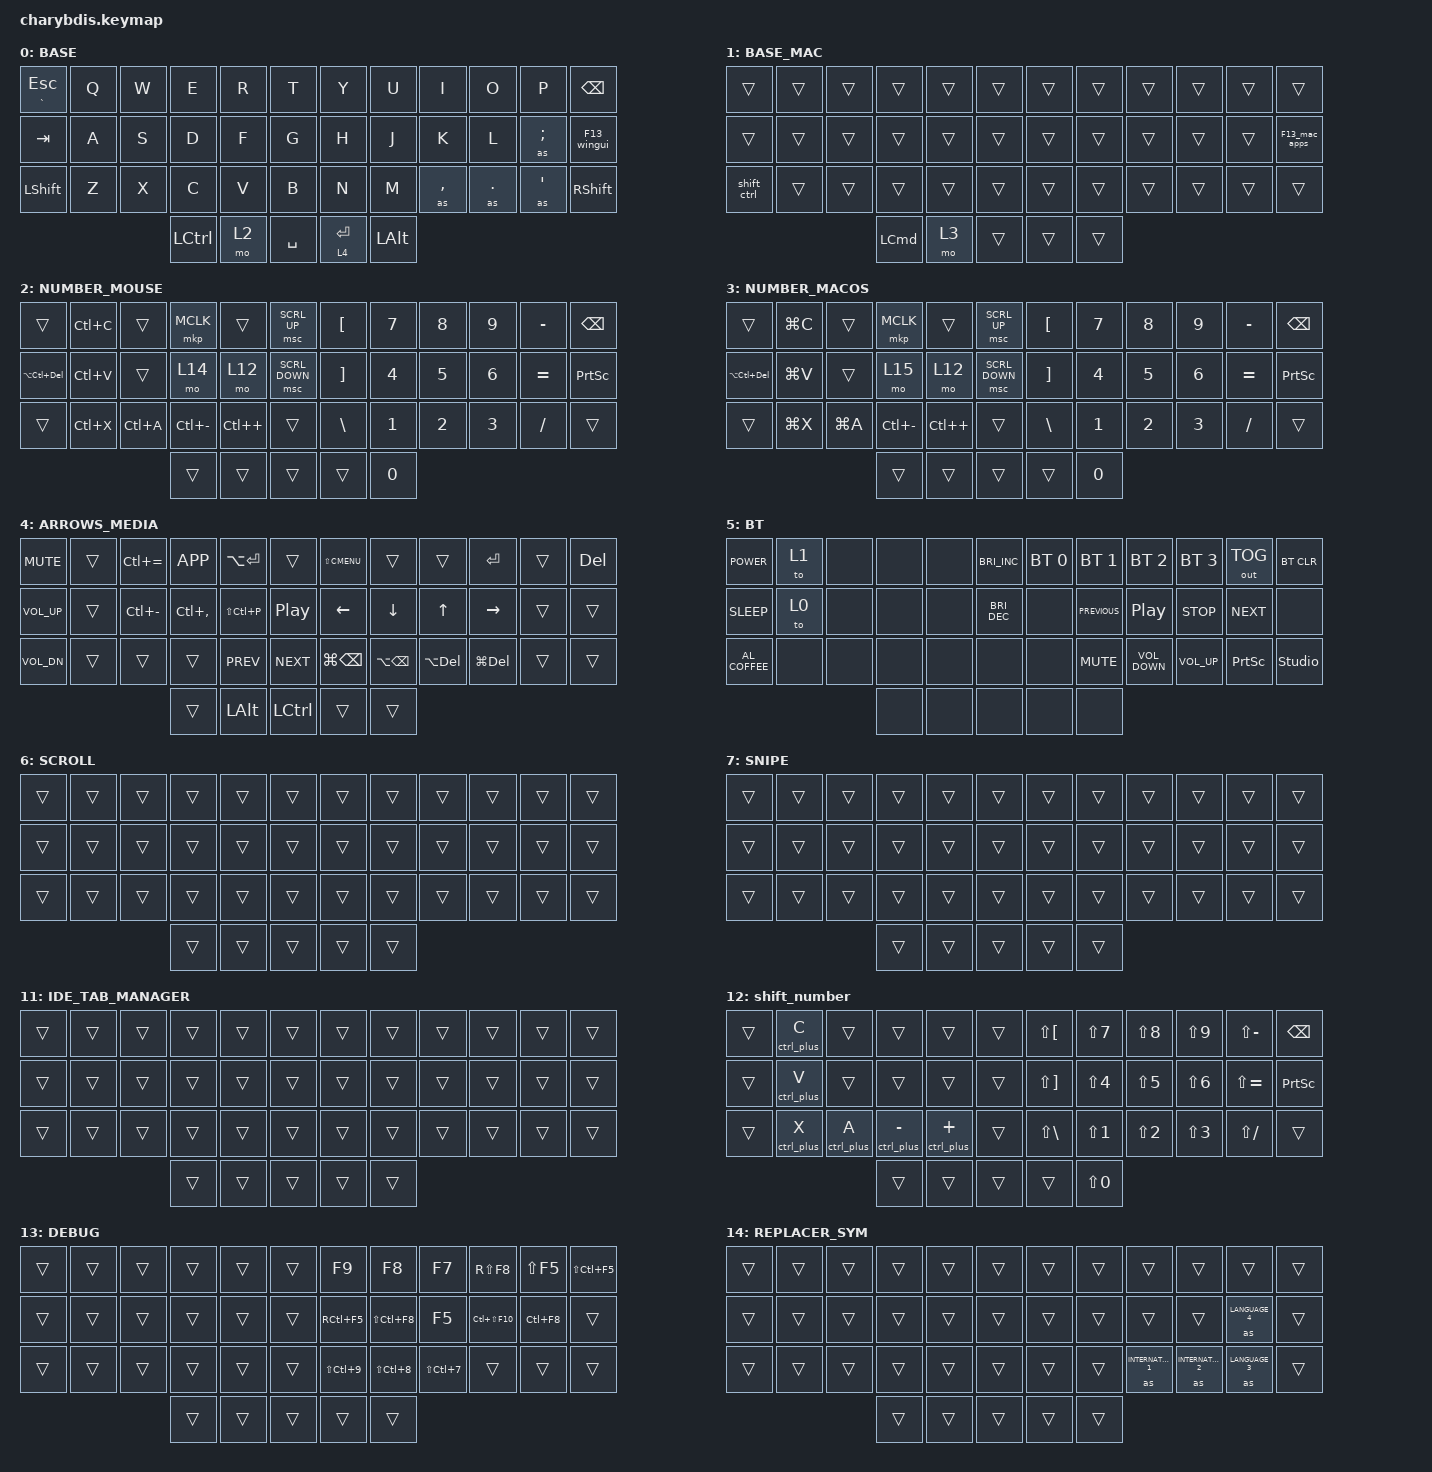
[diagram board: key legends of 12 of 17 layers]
#include <dt-bindings/zmk/mouse.h>
#include <behaviors/mouse_keys.dtsi>

#define MACRO_PLACEHOLDER 0

// #include "macros.dtsi"
// #include "behaviors.dtsi"
// #include "combos.dtsi"
// #include <behaviors.dtsi>

#include <behaviors.dtsi>
#include <dt-bindings/zmk/bt.h>
#include <dt-bindings/zmk/keys.h>
#include <dt-bindings/zmk/outputs.h>
#include <dt-bindings/zmk/pointing.h>

/ {
    /* input config for mouse move mode */

    trackball_listener {
        compatible = "zmk,input-behavior-listener";
        device = <&vtrackball>;
        layers = <0 1 2 3 4 5 7 8 9 10 11 12 13 14 15 16 17>;
        evt-type = <INPUT_EV_REL>;
        x-input-code = <INPUT_REL_X>;
        y-input-code = <INPUT_REL_Y>;
        scale-multiplier = <2>;
        scale-divisor = <5>;

        // bindings = <&ib_toggle_layer 7>;
    };

    /* input config for snipe mode */

    trackball_snipe_listener {
        compatible = "zmk,input-behavior-listener";
        device = <&vtrackball>;
        layers = <7>;
        evt-type = <INPUT_EV_REL>;
        x-input-code = <INPUT_REL_X>;
        y-input-code = <INPUT_REL_Y>;
        scale-multiplier = <1>;
        scale-divisor = <32>;
    };

    /* input config for mouse scroll mode */

    trackball_scroll_listener {
        compatible = "zmk,input-behavior-listener";
        device = <&vtrackball>;
        layers = <6>;
        evt-type = <INPUT_EV_REL>;
        x-input-code = <INPUT_REL_MISC>;
        y-input-code = <INPUT_REL_WHEEL>;
        y-invert;
        bindings = <&ib_wheel_scaler 1 28>;
    };

    /* define a resolution down scaler only for INPUT_REL_WHEEL */

    ib_wheel_scaler: ib_wheel_scaler {
        compatible = "zmk,input-behavior-scaler";
        #binding-cells = <2>;
        evt-type = <INPUT_EV_REL>;
        input-code = <INPUT_REL_WHEEL>;
    };

    /* adjust cooldown waiting period for mouse key layer after activated */

    ib_toggle_layer: ib_toggle_layer {
        compatible = "zmk,input-behavior-tog-layer";
        #binding-cells = <1>;
        time-to-live-ms = <750>;
    };

    // ╭──────┬──────┬──────┬──────┬──────┬──────╮  ╭──────┬──────┬──────┬──────┬──────┬──────╮
    //    00     01     02     03    04      05        06     07     08     09     10     11
    // ├──────┼──────┼──────┼──────┼──────┼──────┤  ├──────┼──────┼──────┼──────┼──────┼──────┤
    //    12     13     14     15    16      17        18     19     20     21     22     23
    // ├──────┼──────┼──────┼──────┼──────┼──────┤  ├──────┼──────┼──────┼──────┼──────┼──────┤
    //    24     25     26     27    28      29        30     31     32     33     34     35
    // ╰──────┴──────┴──────┼──────┼──────┼──────┤  ├──────┼──────┼──────┴──────┴──────┴──────╯
    //                         36     37     38        39     40
    //                      ╰──────┴──────┴──────╯  ╰──────┴──────╯
    // #define BASE    0
    // #define NUM     1
    // #define NAV     2
    // #define SYM     3
    // #define GAME    4
    // #define PHOTOS  5
    // #define EXTRAS  6
    // #define MOUSE   7
    // #define SLOW    8
    // #define SCROLL  9

    macros {
        shift: shift {
            compatible = "zmk,behavior-macro-one-param";
            #binding-cells = <1>;
            bindings =
                <&macro_press>,
                <&kp LEFT_SHIFT>,
                <&macro_tap>,
                <&macro_param_1to1 &kp MACRO_PLACEHOLDER>,
                <&macro_release>,
                <&kp LEFT_SHIFT>;

            label = "SHIFT";
        };

        as: as {
            compatible = "zmk,behavior-macro-one-param";
            #binding-cells = <1>;
            bindings =
                <&macro_press>,
                <&macro_param_1to1 &macro_param_1to2 &as_ht MACRO_PLACEHOLDER MACRO_PLACEHOLDER>,
                <&macro_pause_for_release>,
                <&macro_release>,
                <&macro_param_1to1 &macro_param_1to2 &as_ht MACRO_PLACEHOLDER MACRO_PLACEHOLDER>;

            label = "AS";
        };

        ru_en_toggle: ru_en_toggle {
            compatible = "zmk,behavior-macro";
            #binding-cells = <0>;
            bindings =
                <&macro_press>,
                <&kp LEFT_ALT>,
                <&macro_press>,
                <&kp LEFT_SHIFT>,
                <&macro_release>,
                <&kp LEFT_SHIFT>,
                <&macro_release>,
                <&kp LEFT_ALT>;

            label = "RU_EN_TOGGLE";
        };

        ctrl_plus: ctrl_plus {
            compatible = "zmk,behavior-macro-one-param";
            #binding-cells = <1>;
            bindings =
                <&macro_press>,
                <&kp LEFT_CONTROL &macro_param_1to1>,
                <&macro_tap>,
                <&kp MACRO_PLACEHOLDER>,
                <&macro_release>,
                <&kp LEFT_CONTROL>;

            label = "CTRL_PLUS";
        };

        win_plus: win_plus {
            compatible = "zmk,behavior-macro-one-param";
            #binding-cells = <1>;
            bindings =
                <&macro_press>,
                <&kp LGUI &macro_param_1to1>,
                <&macro_tap>,
                <&kp MACRO_PLACEHOLDER>,
                <&macro_release>,
                <&kp LGUI>;

            label = "WIN_PLUS";
        };
    };

    behaviors {
        as_ht: autoshift_hold_tap {
            compatible = "zmk,behavior-hold-tap";
            label = "AUTOSHIFT_HOLD_TAP";
            bindings = <&shift>, <&kp>;

            #binding-cells = <2>;
            tapping-term-ms = <250>;
            flavor = "tap-preferred";
        };

        ru_en_ht: ru_en_toggle_hold_tap {
            compatible = "zmk,behavior-hold-tap";
            label = "ru_en_toggle_hold_tap";
            bindings = <&mkp>, <&ru_en_toggle>;

            #binding-cells = <2>;
            tapping-term-ms = <190>;
        };

        mo_layer_kp: mo_layer_kp {
            compatible = "zmk,behavior-hold-tap";
            label = "MO_LAYER_KP";
            bindings = <&mo>, <&kp>;

            #binding-cells = <2>;
            tapping-term-ms = <190>;
        };

        ru_en_td: ru_en_td {
            compatible = "zmk,behavior-tap-dance";
            label = "RU_EN_TD";
            #binding-cells = <0>;
            tapping-term-ms = <190>;
            bindings = <&ru_en_ht RCLK 0>, <&kp RIGHT_GUI>;
        };

        F13_wingui: F13_wingui {
            compatible = "zmk,behavior-tap-dance";
            label = "F13_WINGUI";
            #binding-cells = <0>;
            bindings = <&f13_holdtap RCLK F13>, <&kp RIGHT_GUI>;
        };

        F13_mac_apps: F13_mac_apps {
            compatible = "zmk,behavior-tap-dance";
            label = "F13_MAC_APPS";
            #binding-cells = <0>;
            bindings = <&f13_holdtap RCLK F13>, <&kp LG(LA(L))>;
        };

        f13_holdtap: f13_holdtap {
            compatible = "zmk,behavior-hold-tap";
            label = "F13_HOLDTAP";
            bindings = <&mkp>, <&kp>;

            #binding-cells = <2>;
            tapping-term-ms = <190>;
        };

        shift_ctrl: shift_ctrl {
            compatible = "zmk,behavior-tap-dance";
            label = "SHIFT_CTRL";
            #binding-cells = <0>;
            bindings = <&kp LEFT_SHIFT>, <&kp LCTRL>;
        };
    };

    combos {
        compatible = "zmk,combos";

        LAYER_SYSTEM {
            bindings = <&mo 5>;
            key-positions = <38 39>;
        };

        MOUSE_BUTTON {
            bindings = <&mkp LCLK>;
            key-positions = <19 20>;
        };

        SCROLL_TOGGLE {
            bindings = <&tog 6>;
            key-positions = <20 21>;
            timeout-ms = <200>;
        };

        ide_windows {
            bindings = <&mo 8>;
            key-positions = <15 16>;
        };

        snipe_mod {
            bindings = <&tog 7>;
            key-positions = <32 33>;
        };

        windows_layer {
            bindings = <&mo 9>;
            key-positions = <14 15>;
            layers = <0>;
        };

        shift_number {
            bindings = <&mo 12>;
            key-positions = <16 37>;
        };

        debug_layer {
            bindings = <&mo 13>;
            key-positions = <5 4>;
        };

        ai_cursor {
            bindings = <&mo 16>;
            key-positions = <2 4>;
        };

        macos_layers {
            bindings = <&mo 10>;
            key-positions = <14 15>;
            layers = <1>;
        };

        homerow {
            bindings = <&kp LG(LC(H))>;
            key-positions = <8 19>;
            layers = <1>;
        };
    };

    keymap {
        compatible = "zmk,keymap";

        BASE {
            bindings = <
&mt GRAVE ESCAPE  &kp Q  &kp W  &kp E             &kp R  &kp T        &kp Y         &kp U         &kp I      &kp O    &kp P             &kp BSPC
&kp TAB           &kp A  &kp S  &kp D             &kp F  &kp G        &kp H         &kp J         &kp K      &kp L    &as SEMICOLON     &F13_wingui
&kp LSHFT         &kp Z  &kp X  &kp C             &kp V  &kp B        &kp N         &kp M         &as COMMA  &as DOT  &as SINGLE_QUOTE  &kp RSHFT
                                &kp LEFT_CONTROL  &mo 2  &kp SPACE    &lt 4 RETURN  &kp LEFT_ALT
            >;
        };

        BASE_MAC {
            bindings = <
&trans       &trans  &trans  &trans    &trans  &trans    &trans  &trans  &trans  &trans  &trans  &trans
&trans       &trans  &trans  &trans    &trans  &trans    &trans  &trans  &trans  &trans  &trans  &F13_mac_apps
&shift_ctrl  &trans  &trans  &trans    &trans  &trans    &trans  &trans  &trans  &trans  &trans  &trans
                             &kp LCMD  &mo 3   &trans    &trans  &trans
            >;
        };

        NUMBER_MOUSE {
            bindings = <
&trans              &kp LC(C)  &trans     &mkp MCLK      &trans        &msc SCRL_UP      &kp LEFT_BRACKET   &kp N7  &kp N8  &kp N9        &kp MINUS  &kp BACKSPACE
&kp LA(LC(DELETE))  &kp LC(V)  &trans     &mo 14         &mo 12        &msc SCRL_DOWN    &kp RIGHT_BRACKET  &kp N4  &kp N5  &kp NUMBER_6  &kp EQUAL  &kp PRINTSCREEN
&trans              &kp LC(X)  &kp LC(A)  &kp LC(MINUS)  &kp LC(PLUS)  &trans            &kp BACKSLASH      &kp N1  &kp N2  &kp N3        &kp SLASH  &trans
                                          &trans         &trans        &trans            &trans             &kp N0
            >;
        };

        NUMBER_MACOS {
            bindings = <
&trans              &kp LG(C)  &trans     &mkp MCLK      &trans        &msc SCRL_UP      &kp LEFT_BRACKET   &kp N7  &kp N8  &kp N9        &kp MINUS  &kp BACKSPACE
&kp LA(LC(DELETE))  &kp LG(V)  &trans     &mo 15         &mo 12        &msc SCRL_DOWN    &kp RIGHT_BRACKET  &kp N4  &kp N5  &kp NUMBER_6  &kp EQUAL  &kp PRINTSCREEN
&trans              &kp LG(X)  &kp LG(A)  &kp LC(MINUS)  &kp LC(PLUS)  &trans            &kp BACKSLASH      &kp N1  &kp N2  &kp N3        &kp SLASH  &trans
                                          &trans         &trans        &trans            &trans             &kp N0
            >;
        };

        ARROWS_MEDIA {
            bindings = <
&kp C_MUTE       &trans  &kp LC(EQUAL)  &kp K_APP      &kp LA(ENTER)  &trans              &kp LS(K_CMENU)    &trans             &trans          &kp ENTER       &trans  &kp DEL
&kp C_VOLUME_UP  &trans  &kp LC(MINUS)  &kp LC(COMMA)  &kp LS(LC(P))  &kp C_PLAY_PAUSE    &kp LEFT           &kp DOWN_ARROW     &kp UP          &kp RIGHT       &trans  &trans
&kp C_VOL_DN     &trans  &trans         &trans         &kp C_PREV     &kp C_NEXT          &kp LG(BACKSPACE)  &kp LA(BACKSPACE)  &kp LA(DELETE)  &kp LG(DELETE)  &trans  &trans
                                        &trans         &kp LEFT_ALT   &kp LCTRL           &trans             &trans
            >;
        };

        BT {
            bindings = <
&kp C_POWER      &to 1  &none  &none  &none  &kp C_BRIGHTNESS_INC    &bt BT_SEL 0  &bt BT_SEL 1    &bt BT_SEL 2       &bt BT_SEL 3     &out OUT_TOG     &bt BT_CLR
&kp C_SLEEP      &to 0  &none  &none  &none  &kp C_BRIGHTNESS_DEC    &none         &kp C_PREVIOUS  &kp C_PLAY_PAUSE   &kp C_STOP       &kp C_NEXT       &none
&kp C_AL_COFFEE  &none  &none  &none  &none  &none                   &none         &kp K_MUTE      &kp C_VOLUME_DOWN  &kp C_VOLUME_UP  &kp PRINTSCREEN  &studio_unlock
                               &none  &none  &none                   &none         &none
            >;
        };

        SCROLL {
            bindings = <
&trans  &trans  &trans  &trans  &trans  &trans    &trans  &trans  &trans  &trans  &trans  &trans
&trans  &trans  &trans  &trans  &trans  &trans    &trans  &trans  &trans  &trans  &trans  &trans
&trans  &trans  &trans  &trans  &trans  &trans    &trans  &trans  &trans  &trans  &trans  &trans
                        &trans  &trans  &trans    &trans  &trans
            >;
        };

        SNIPE {
            bindings = <
&trans  &trans  &trans  &trans  &trans  &trans    &trans  &trans  &trans  &trans  &trans  &trans
&trans  &trans  &trans  &trans  &trans  &trans    &trans  &trans  &trans  &trans  &trans  &trans
&trans  &trans  &trans  &trans  &trans  &trans    &trans  &trans  &trans  &trans  &trans  &trans
                        &trans  &trans  &trans    &trans  &trans
            >;
        };

        IDE_WINDOW {
            bindings = <
&trans  &trans  &trans  &trans                     &trans                    &trans                 &kp LA(N0)         &kp LA(N7)        &kp LA(N8)        &kp LA(N9)        &kp LA(MINUS)      &kp LA(F1)
&trans  &trans  &trans  &trans                     &trans                    &trans                 &trans             &kp LA(NUMBER_4)  &kp LA(N5)        &kp LA(N6)        &kp LA(EQUAL)      &kp LC(LA(N2))
&trans  &trans  &trans  &trans                     &trans                    &trans                 &kp LA(LS(LC(O)))  &kp LA(NUMBER_1)  &kp LA(NUMBER_2)  &kp LA(NUMBER_3)  &kp LA(BACKSLASH)  &trans
                        &kp LC(LA(RIGHT_BRACKET))  &kp LA(LC(LEFT_BRACKET))  &kp LA(LC(LS(DOT)))    &trans             &trans
            >;
        };

        WINDOWS_LAYER {
            bindings = <
&trans  &trans  &trans  &trans  &kp LA(F4)     &kp LS(LC(F4))    &kp LS(LG(LEFT))    &kp LA(TAB)         &kp LG(TAB)        &kp LS(LG(RIGHT))    &kp LS(LC(LG(LEFT)))  &kp LS(LC(LG(RIGHT)))
&trans  &trans  &trans  &trans  &kp LG(LC(T))  &kp LS(LC(F5))    &win_plus LG(LEFT)  &win_plus LG(DOWN)  &win_plus LG(UP)   &win_plus LG(RIGHT)  &kp LS(LG(Q))         &kp LS(LA(LC(V)))
&trans  &trans  &trans  &trans  &trans         &trans            &kp LC(LG(LEFT))    &kp LA(LG(LEFT))    &kp LA(LG(RIGHT))  &kp LC(LG(RIGHT))    &kp LS(LC(LG(F)))     &kp LA(LS(LC(B)))
                        &trans  &trans         &trans            &kp LS(LC(F5))      &trans
            >;
        };

        MACOS_LAYER {
            bindings = <
&trans  &trans  &trans  &trans  &kp LG(Q)      &kp LC(LA(ENTER))    &kp LS(LG(LEFT))  &kp LA(TAB)       &kp LG(TAB)        &kp LS(LG(RIGHT))  &kp LS(LG(LEFT))   &kp LS(LG(RIGHT))
&trans  &trans  &trans  &trans  &kp LG(LC(T))  &kp LS(LC(F5))       &kp LS(LC(LEFT))  &kp LG(DOWN)      &kp LG(UP)         &kp LS(LC(RIGHT))  &kp LS(LG(Q))      &kp LS(LA(LC(V)))
&trans  &trans  &trans  &trans  &trans         &trans               &kp LC(LG(LEFT))  &kp LA(LG(LEFT))  &kp LA(LG(RIGHT))  &kp LC(LG(RIGHT))  &kp LS(LC(LG(F)))  &kp LA(LS(LC(B)))
                        &trans  &trans         &trans               &kp LS(LC(F5))    &trans
            >;
        };

        IDE_TAB_MANAGER {
            bindings = <
&trans  &trans  &trans  &trans  &trans  &trans    &trans  &trans  &trans  &trans  &trans  &trans
&trans  &trans  &trans  &trans  &trans  &trans    &trans  &trans  &trans  &trans  &trans  &trans
&trans  &trans  &trans  &trans  &trans  &trans    &trans  &trans  &trans  &trans  &trans  &trans
                        &trans  &trans  &trans    &trans  &trans
            >;
        };

        shift_number {
            bindings = <
&trans  &ctrl_plus C  &trans        &trans            &trans           &trans    &kp LS(LEFT_BRACKET)   &kp LS(N7)  &kp LS(N8)  &kp LS(N9)        &kp LS(MINUS)  &kp BACKSPACE
&trans  &ctrl_plus V  &trans        &trans            &trans           &trans    &kp LS(RIGHT_BRACKET)  &kp LS(N4)  &kp LS(N5)  &kp LS(NUMBER_6)  &kp LS(EQUAL)  &kp PRINTSCREEN
&trans  &ctrl_plus X  &ctrl_plus A  &ctrl_plus MINUS  &ctrl_plus PLUS  &trans    &kp LS(BACKSLASH)      &kp LS(N1)  &kp LS(N2)  &kp LS(N3)        &kp LS(SLASH)  &trans
                                    &trans            &trans           &trans    &trans                 &kp LS(N0)
            >;
        };

        DEBUG {
            bindings = <
&trans  &trans  &trans  &trans  &trans  &trans    &kp F9          &kp F8          &kp F7          &kp RS(F8)       &kp LS(F5)  &kp LS(LC(F5))
&trans  &trans  &trans  &trans  &trans  &trans    &kp RC(F5)      &kp LS(LC(F8))  &kp F5          &kp LC(LS(F10))  &kp LC(F8)  &trans
&trans  &trans  &trans  &trans  &trans  &trans    &kp LS(LC(N9))  &kp LS(LC(N8))  &kp LS(LC(N7))  &trans           &trans      &trans
                        &trans  &trans  &trans    &trans          &trans
            >;
        };

        REPLACER_SYM {
            bindings = <
&trans  &trans  &trans  &trans  &trans  &trans    &trans  &trans  &trans               &trans               &trans          &trans
&trans  &trans  &trans  &trans  &trans  &trans    &trans  &trans  &trans               &trans               &as LANGUAGE_4  &trans
&trans  &trans  &trans  &trans  &trans  &trans    &trans  &trans  &as INTERNATIONAL_1  &as INTERNATIONAL_2  &as LANGUAGE_3  &trans
                        &trans  &trans  &trans    &trans  &trans
            >;
        };

        REPLACE_SYM_MAC {
            bindings = <
&trans  &trans  &trans  &trans  &trans  &trans    &trans  &trans  &trans    &trans        &trans        &trans
&trans  &trans  &trans  &trans  &trans  &trans    &trans  &trans  &trans    &trans        &as LC(INT1)  &trans
&trans  &trans  &trans  &trans  &trans  &trans    &trans  &trans  &as INT1  &as LA(INT1)  &as LG(INT1)  &trans
                        &trans  &trans  &trans    &trans  &trans
            >;
        };

        AI_CURSOR {
            bindings = <
&trans  &trans  &trans  &trans  &trans  &trans    &trans  &kp LC(N)              &kp LC(LS(Y))  &trans  &trans  &trans
&trans  &trans  &trans  &trans  &trans  &trans    &trans  &kp LA(J)              &kp LA(K)      &trans  &trans  &trans
&trans  &trans  &trans  &trans  &trans  &trans    &trans  &kp LC(LS(BACKSPACE))  &kp LC(ENTER)  &trans  &trans  &trans
                        &trans  &trans  &trans    &trans  &trans
            >;
        };
    };
};
